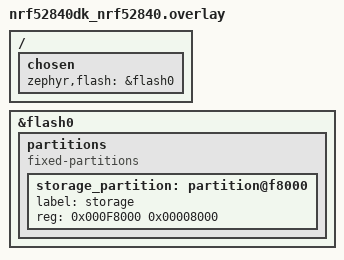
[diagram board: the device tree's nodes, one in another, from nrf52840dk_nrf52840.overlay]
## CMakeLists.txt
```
 # Minimum version of CMake required to build this project
cmake_minimum_required(VERSION 3.20.0)
 
# Load the Zephyr build system
# ZEPHYR_BASE is an environment variable set during SDK installation
find_package(Zephyr REQUIRED HINTS $ENV{ZEPHYR_BASE})
 
# Give your project a name
project(ble_tracker)
 
# Tell CMake which source files to include in the build
# Add a new line here every time you create a new .c file
target_sources(app PRIVATE
    src/main.c
    src/tracker_service.c
    src/ble/ble_security.c
)
```

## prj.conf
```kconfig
CONFIG_LOG=y
CONFIG_BT=y
CONFIG_BT_PERIPHERAL=y
CONFIG_BT_DEVICE_NAME="RishiTracker"
CONFIG_MAIN_STACK_SIZE=2048
CONFIG_BT_RX_STACK_SIZE=2048
CONFIG_BT_SMP=y
CONFIG_BT_BONDABLE=y
CONFIG_BT_SETTINGS=y
CONFIG_FLASH=y
CONFIG_FLASH_PAGE_LAYOUT=y
CONFIG_FLASH_MAP=y
CONFIG_NVS=y
CONFIG_SETTINGS=y
CONFIG_DK_LIBRARY=y
```

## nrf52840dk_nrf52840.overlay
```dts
/ {
    chosen {
        zephyr,flash = &flash0;
    };
};

&flash0 {
    partitions {
        compatible = "fixed-partitions";

        storage_partition: partition@f8000 {
            label = "storage";
            reg = <0x000F8000 0x00008000>;
        };
    };
};
```

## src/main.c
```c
#include <zephyr/kernel.h>
#include <zephyr/bluetooth/bluetooth.h>
#include <zephyr/bluetooth/conn.h>
#include <zephyr/logging/log.h>
#include "tracker_service.h"
#include "ble/ble_security.h"
#include <zephyr/settings/settings.h>
LOG_MODULE_REGISTER(main, LOG_LEVEL_DBG);

static const struct bt_data advertising_data[] = {
    BT_DATA_BYTES(BT_DATA_FLAGS, BT_LE_AD_GENERAL | BT_LE_AD_NO_BREDR),
};
static void start_advertising(void);

static struct k_work adv_work;

static void adv_work_handler(struct k_work *work)
{
    start_advertising();
}
 // errif 0= connected successfully
static void on_connected(struct bt_conn *conn, uint8_t err)
{
    if (err != 0)
    {
        LOG_ERR("Connection attempt failed. Error code: %d", err);
        start_advertising();
        return;
    }
    LOG_INF("A device just connected!");
}
//   0x08 → Connection timed out (signal lost)
 //   0x13 → Remote device disconnected (phone closed app)
 //   0x16 → We disconnected ourselves (local host terminated)
static void on_disconnected(struct bt_conn *conn, uint8_t reason)
{
    LOG_INF("Device disconnected. Reason code: 0x%02X", reason);
    LOG_INF("Re-starting advertising so we can be found again...");
    k_work_submit(&adv_work);
}
// This tells Zephyr which functions to call for connection events.
BT_CONN_CB_DEFINE(connection_callbacks) = {
    .connected    = on_connected,
    .disconnected = on_disconnected,
};
static void start_advertising(void)
{
    int result;
     //the function that actually starts the radio
    result = bt_le_adv_start(
    BT_LE_ADV_CONN_FAST_1,
    advertising_data,
    ARRAY_SIZE(advertising_data),
    NULL,
    0
);
    // Check if advertising failed to start
    if (result != 0)
    {
        LOG_ERR("Failed to start advertising! Error code: %d", result);
        return;
    }
    LOG_INF("Advertising started!");
}
static void on_bluetooth_ready(int err)
{
    if (err != 0)
    {
        LOG_ERR("Bluetooth failed to initialize! Error: %d", err);
        return;
    }
    LOG_INF("Bluetooth hardware is ready!");
    tracker_service_init();

    // Register pairing/bonding behaviour (passkey callbacks, bond-clear button)
    err = ble_security_init();
    if (err != 0)
    {
        LOG_ERR("Failed to initialize BLE security! Error: %d", err);
        return;
    }

    // Restore any bonds saved from a previous session, BEFORE advertising starts
    if (IS_ENABLED(CONFIG_SETTINGS))
    {
        settings_load();
    }

    start_advertising();
}
int main(void)
{
    int result;
    LOG_INF("  TrackerDK BLE Peripheral Starting...  ");
    k_work_init(&adv_work, adv_work_handler);
    result = bt_enable(on_bluetooth_ready);
    if (result != 0)
    {
        LOG_ERR("bt_enable() failed! BLE cannot start. Error: %d", result);
        return result;
    }
    LOG_INF("BLE initialization started, waiting for hardware...");
    while (1)
    {
        LOG_INF("Main thread alive");
        k_sleep(K_SECONDS(5));
    }
    return 0;
}
```

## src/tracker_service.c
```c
#include <zephyr/bluetooth/bluetooth.h>
#include <zephyr/bluetooth/gatt.h>
#include <zephyr/logging/log.h>
#include "tracker_service.h"
LOG_MODULE_REGISTER(tracker_service, LOG_LEVEL_DBG);
#define MY_SERVICE_UUID BT_UUID_DECLARE_128(BT_UUID_128_ENCODE(0x12345678, 0x1234, 0x5678, 0x1234, 0x56789abcdef0))
#define MY_CHAR_UUID    BT_UUID_DECLARE_128(BT_UUID_128_ENCODE(0x12345678, 0x1234, 0x5678, 0x1234, 0x56789abcdef1))
static uint8_t sensor_value = 0x42;
static ssize_t on_characteristic_read(struct bt_conn *conn, const struct bt_gatt_attr *attr, void *buf, uint16_t len, uint16_t offset)
{
    LOG_INF("Read! Sending value: 0x%02X (%d)", sensor_value, sensor_value);
    return bt_gatt_attr_read(conn, attr, buf, len, offset, &sensor_value, sizeof(sensor_value));
}
BT_GATT_SERVICE_DEFINE(tracker_gatt_service,
    BT_GATT_PRIMARY_SERVICE(MY_SERVICE_UUID),
    BT_GATT_CHARACTERISTIC(MY_CHAR_UUID, BT_GATT_CHRC_READ, BT_GATT_PERM_READ_AUTHEN, on_characteristic_read, NULL, NULL),
);
int tracker_service_init(void)
{
    LOG_INF("GATT service ready. Characteristic value = 0x%02X", sensor_value);
    return 0;
}
int tracker_service_set_value(uint8_t new_value)
{
    sensor_value = new_value;
    LOG_INF("Value updated to 0x%02X (%d decimal)", new_value, new_value);
    return 0;
}
```
